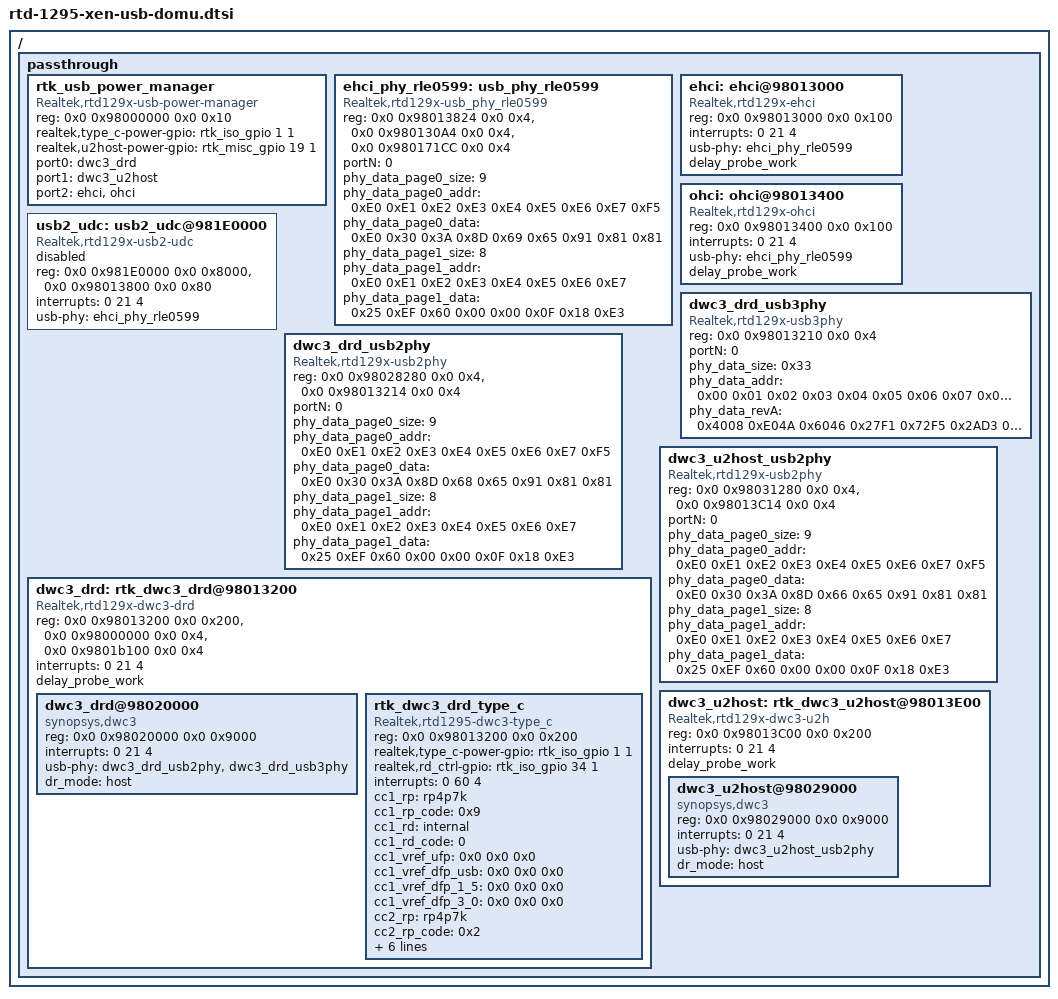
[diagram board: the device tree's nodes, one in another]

/ {

	passthrough {

	rtk_usb_power_manager {
		compatible = "Realtek,rtd129x-usb-power-manager";
		reg = <0x0 0x98000000 0x0 0x10>;
		realtek,type_c-power-gpio = <&rtk_iso_gpio 1 1 0>; /*TypeC power, output, default low */
		realtek,u2host-power-gpio = <&rtk_misc_gpio 19 1 0>; /*ehci and u2host power, output, default low */
		//realtek,u3host-power-gpio = <&rtk_iso_gpio 32 1 0>; /*1296 u3host power, output, default low */
		port0 = <&dwc3_drd>;
		port1 = <&dwc3_u2host>;
		port2 = <&ehci &ohci>;
		//port3 = <&dwc3_u3host>;
	};

	ehci_phy_rle0599: usb_phy_rle0599 {
		compatible = "Realtek,rtd129x-usb_phy_rle0599";
		reg = <0x0 0x98013824 0x0 0x4>, <0x0 0x980130A4 0x0 0x4>, <0x0 0x980171CC 0x0 0x4>;
		//Note reg addr: REG_WRAP_VStatusOut2, REG_EHCI_INSNREG05, REG_EFUSE71cc
		portN = <0>;
		phy_data_page0_size = <9>;
		phy_data_page0_addr = /bits/ 8 <0xE0 0xE1 0xE2 0xE3 0xE4 0xE5 0xE6 0xE7 0xF5>;
		phy_data_page0_data = /bits/ 8 <0xE0 0x30 0x3A 0x8D 0x69 0x65 0x91 0x81 0x81>;
		phy_data_page1_size = <8>;
		phy_data_page1_addr = /bits/ 8 <0xE0 0xE1 0xE2 0xE3 0xE4 0xE5 0xE6 0xE7>;
		phy_data_page1_data = /bits/ 8 <0x25 0xEF 0x60 0x00 0x00 0x0F 0x18 0xE3>;
		status = "okay";
	};

	ehci: ehci@98013000 {
		compatible = "Realtek,rtd129x-ehci";
		reg = <0x0 0x98013000 0x0 0x100>;
		interrupts = <0 21 4>;
		usb-phy = <&ehci_phy_rle0599>;
		delay_probe_work; //To delay probe work
		status = "okay";
	};

	ohci: ohci@98013400 {
		compatible = "Realtek,rtd129x-ohci";
		reg = <0x0 0x98013400 0x0 0x100>;
		interrupts = <0 21 4>;
		usb-phy = <&ehci_phy_rle0599>;
		delay_probe_work; //To delay probe work
		status = "okay";
	};

	usb2_udc: usb2_udc@981E0000 {
		compatible = "Realtek,rtd129x-usb2-udc";
		reg = <0x0 0x981E0000 0x0 0x8000>, <0x0 0x98013800 0x0 0x80>;
		interrupts = <0 21 4>;
		usb-phy = <&ehci_phy_rle0599>;

		status = "disable";
	};

	dwc3_drd_usb3phy: dwc3_drd_usb3phy {
		compatible = "Realtek,rtd129x-usb3phy";
		reg = <0x0 0x98013210 0x0 0x4>;
		#address-cells = <2>;
		#size-cells = <2>;
		ranges;
		portN = <0>;
		phy_data_size = <0x33>;
		phy_data_addr = /bits/ 8
			<0x00   0x01   0x02   0x03   0x04   0x05   0x06   0x07   0x08   0x09   0x0A   0x0B   0x0C   0x0D   0x0E   0x0F
			 0x10   0x11   0x12   0x13   0x14   0x15   0x16   0x17   0x18   0x19   0x1A   0x1B   0x1C   0x1D   0x1E   0x1F
			 0x20   0x21   0x22   0x23   0x24   0x25   0x26   0x27   0x28   0x29   0x2A   0x2B   0x2C   0x2D   0x2E   0x2F
			 0x09   0x09   0x09>;
		phy_data_revA = /bits/ 16
			<0x4008 0xE04A 0x6046 0x27F1 0x72F5 0x2AD3 0x000E 0x2E00 0x3591 0x521C 0xA600 0xA905 0xC000 0xEF1C 0x2000 0x0000
			 0x000C 0x4C00 0xFC00 0x0C81 0xDE01 0x0000 0x0000 0x0000 0x0000 0x4004 0x1260 0xFF00 0xCB00 0xA03F 0xC2E0 0x2807
			 0x945A 0x88AA 0x0057 0xAB66 0x0800 0x0000 0x040A 0x01D6 0xF842 0x3080 0x3082 0x2078 0xFFFF 0xFFFF 0x0000 0x0040
			 0x521C 0x501C 0x521C>;
		status = "okay";
	};

	dwc3_drd_usb2phy: dwc3_drd_usb2phy {
		compatible = "Realtek,rtd129x-usb2phy";
		reg = <0x0 0x98028280 0x0 0x4>, <0x0 0x98013214 0x0 0x4>;
		#address-cells = <2>;
		#size-cells = <2>;
		ranges;
		portN = <0>;
		phy_data_page0_size = <9>;
		phy_data_page0_addr = /bits/ 8 <0xE0 0xE1 0xE2 0xE3 0xE4 0xE5 0xE6 0xE7 0xF5>;
		phy_data_page0_data = /bits/ 8 <0xE0 0x30 0x3A 0x8D 0x68 0x65 0x91 0x81 0x81>;
		phy_data_page1_size = <8>;
		phy_data_page1_addr = /bits/ 8 <0xE0 0xE1 0xE2 0xE3 0xE4 0xE5 0xE6 0xE7>;
		phy_data_page1_data = /bits/ 8 <0x25 0xEF 0x60 0x00 0x00 0x0F 0x18 0xE3>;
		status = "okay";
	};

	dwc3_drd: rtk_dwc3_drd@98013200 {
		compatible = "Realtek,rtd129x-dwc3-drd";
		reg = <0x0 0x98013200 0x0 0x200>, <0x0 0x98000000 0x0 0x4>, <0x0 0x9801b100 0x0 0x4>;
		interrupts = <0 21 4>;
		#address-cells = <2>;
		#size-cells = <2>;
		ranges;
		delay_probe_work; //To delay probe work
		status = "okay";

		dwc3_drd@98020000 {
			compatible = "synopsys,dwc3";
			reg = <0x0 0x98020000 0x0 0x9000>;
			interrupts = <0 21 4>;
			usb-phy = <&dwc3_drd_usb2phy &dwc3_drd_usb3phy>;
			dr_mode = "host";               /*otg, host, peripheral*/
			//tx-fifo-resize;
		};

		rtk_dwc3_drd_type_c {
			compatible = "Realtek,rtd1295-dwc3-type_c";
			reg = <0x0 0x98013200 0x0 0x200>;
			realtek,type_c-power-gpio = <&rtk_iso_gpio 1 1 0>; 	/*TypeC power, output, default low */
			realtek,rd_ctrl-gpio = <&rtk_iso_gpio 34 1 0>; 	/*TypeC Rd control, output, default low */
			interrupts = <0 60 4>;
			cc1_rp = "rp4p7k"; /*rp4p7k, rp36k, rp12k*/
			cc1_rp_code = <0x9>;
			cc1_rd = "internal"; /*internal, extrenal*/
			cc1_rd_code = <0>; /*for internal rd*/
			cc1_vref_ufp     = /bits/ 8 <0x0 0x0 0x0>; /*<1p23v,0p66v,0p4v,0p2v>*/
			cc1_vref_dfp_usb = /bits/ 8 <0x0 0x0 0x0>; /*<0_1p6v,0p2v,unused>*/
			cc1_vref_dfp_1_5 = /bits/ 8 <0x0 0x0 0x0>; /*<1_1p6v,0p4v,0p2v>*/
			cc1_vref_dfp_3_0 = /bits/ 8 <0x0 0x0 0x0>; /*<2p6v,0p8v,0p2v>*/
			cc2_rp = "rp4p7k"; /*rp4p7k, rp36k, rp12k*/
			cc2_rp_code = <0x2>;
			cc2_rd = "internal"; /*internal, extrenal*/
			cc2_rd_code = <0>; /*for internal rd*/
			cc2_vref_ufp     = /bits/ 8 <0x0 0x0 0x0>; /*<1p23v,0p66v,0p4v,0p2v>*/
			cc2_vref_dfp_usb = /bits/ 8 <0x0 0x0 0x0>; /*<0_1p6v,0p2v,unused>*/
			cc2_vref_dfp_1_5 = /bits/ 8 <0x0 0x0 0x0>; /*<1_1p6v,0p4v,0p2v>*/
			cc2_vref_dfp_3_0 = /bits/ 8 <0x0 0x0 0x0>; /*<2p6v,0p8v,0p2v>*/
			//drd_mode;  /*depend on dwc3 dr_mode = "peripheral"*/
			//debug; /*to enable debug log*/
		};
	};

	dwc3_u2host_usb2phy: dwc3_u2host_usb2phy {
		compatible = "Realtek,rtd129x-usb2phy";
		reg = <0x0 0x98031280 0x0 0x4>, <0x0 0x98013C14 0x0 0x4>;
		#address-cells = <2>;
		#size-cells = <2>;
		ranges;
		portN = <0>;
		phy_data_page0_size = <9>;
		phy_data_page0_addr = /bits/ 8 <0xE0 0xE1 0xE2 0xE3 0xE4 0xE5 0xE6 0xE7 0xF5>;
		phy_data_page0_data = /bits/ 8 <0xE0 0x30 0x3A 0x8D 0x66 0x65 0x91 0x81 0x81>;
		phy_data_page1_size = <8>;
		phy_data_page1_addr = /bits/ 8 <0xE0 0xE1 0xE2 0xE3 0xE4 0xE5 0xE6 0xE7>;
		phy_data_page1_data = /bits/ 8 <0x25 0xEF 0x60 0x00 0x00 0x0F 0x18 0xE3>;
		status = "okay";
	};

	dwc3_u2host: rtk_dwc3_u2host@98013E00 {
		compatible = "Realtek,rtd129x-dwc3-u2h";
		reg = <0x0 0x98013C00 0x0 0x200>;
		interrupts = <0 21 4>;
		#address-cells = <2>;
		#size-cells = <2>;
		ranges;
		delay_probe_work; //To delay probe work
		status = "okay";

		dwc3_u2host@98029000 {
			compatible = "synopsys,dwc3";
			reg = <0x0 0x98029000 0x0 0x9000>;
			interrupts = <0 21 4>;
			usb-phy = <&dwc3_u2host_usb2phy>;
			dr_mode = "host";               /*only host*/
			//tx-fifo-resize;
		};
	};


//	dwc3_u3host_usb3phy: dwc3_u3host_usb3phy {
//		compatible = "Realtek,rtd1295-usb3phy";
//		reg = <0x98013E10 0x4>;
//		#address-cells = <1>;
//		#size-cells = <1>;
//		ranges;
//		portN = <0>;
//		phy_data_size = <0x33>;
//		phy_data_addr = /bits/ 8    <0x00   0x01   0x02   0x03   0x04   0x05   0x06   0x07   0x08   0x09   0x0A   0x0B   0x0C   0x0D   0x0E   0x0F
//                                     0x10   0x11   0x12   0x13   0x14   0x15   0x16   0x17   0x18   0x19   0x1A   0x1B   0x1C   0x1D   0x1E   0x1F
//                                     0x20   0x21   0x22   0x23   0x24   0x25   0x26   0x27   0x28   0x29   0x2A   0x2B   0x2C   0x2D   0x2E   0x2F
//                                     0x09   0x09   0x09>;
//		phy_data_revA = /bits/ 16 <0x4008 0xA844 0x6042 0x2771 0xB2F5 0xEAD6 0x0003 0x3210 0x3590 0x325C 0x9643 0xE909 0xC000 0xF53C 0x2000 0x0E94
//                                   0x000C 0x4C00 0xFC00 0x0C81 0xDE01 0x0000 0x0000 0x0000 0x0000 0x7004 0x1260 0xFF0C 0xCB00 0xA03F 0xC200 0x5006
//                                   0xD4AA 0x585A 0x00D3 0xAB64 0x0800 0x0000 0x047A 0x01D6 0xF882 0x3080 0x3083 0x2038 0xFFFF 0xFFFF 0x0000 0x0040
//                                   0x325C 0x305C 0x325C>;
//	};

//	dwc3_u3host_usb2phy: dwc3_u3host_usb2phy {
//		compatible = "Realtek,rtd1295-usb2phy";
//		reg = <0x981F8280 0x4>, <0x98013E14 0x4>;
//		#address-cells = <1>;
//		#size-cells = <1>;
//		ranges;
//		portN = <0>;
//		phy_data_page0_size = <10>;
//		phy_data_page0_addr = /bits/ 8 <0xE0 0xE1 0xE2 0xE3 0xE4 0xE5 0xE6 0xE7 0xF0 0xF1>;
//		phy_data_page0_data = /bits/ 8 <0xE3 0x18 0x98 0xCD 0x68 0x25 0x81 0x81 0xFC 0x8C>;
//		phy_data_page1_size = <8>;
//		phy_data_page1_addr = /bits/ 8 <0xE0 0xE1 0xE2 0xE3 0xE4 0xE5 0xE6 0xE7>;
//		phy_data_page1_data = /bits/ 8 <0x25 0x77 0x04 0x00 0x00 0x0F 0x58 0xE3>;
//	};

//	dwc3_u3host: rtk_dwc3_u3host@98013E00 {
//		compatible = "Realtek,rtd1295-dwc3-u3h";
//		reg = <0x98013E00 0x200>, <0x98000000 0x4>, <0x9801b100 0x4>;
//		interrupts = <0 21 4>;
//		#address-cells = <1>;
//		#size-cells = <1>;
//		ranges;
//		dwc3_u3host@981F0000 {
//			compatible = "synopsys,dwc3";
//			reg = <0x981F0000 0x9000>;
//			interrupts = <0 21 4>;
//			usb-phy = <&dwc3_u3host_usb2phy &dwc3_u3host_usb3phy>;
//			dr_mode = "host";               /*only host*/
//			//tx-fifo-resize;
//		};
//	};

	};
};
